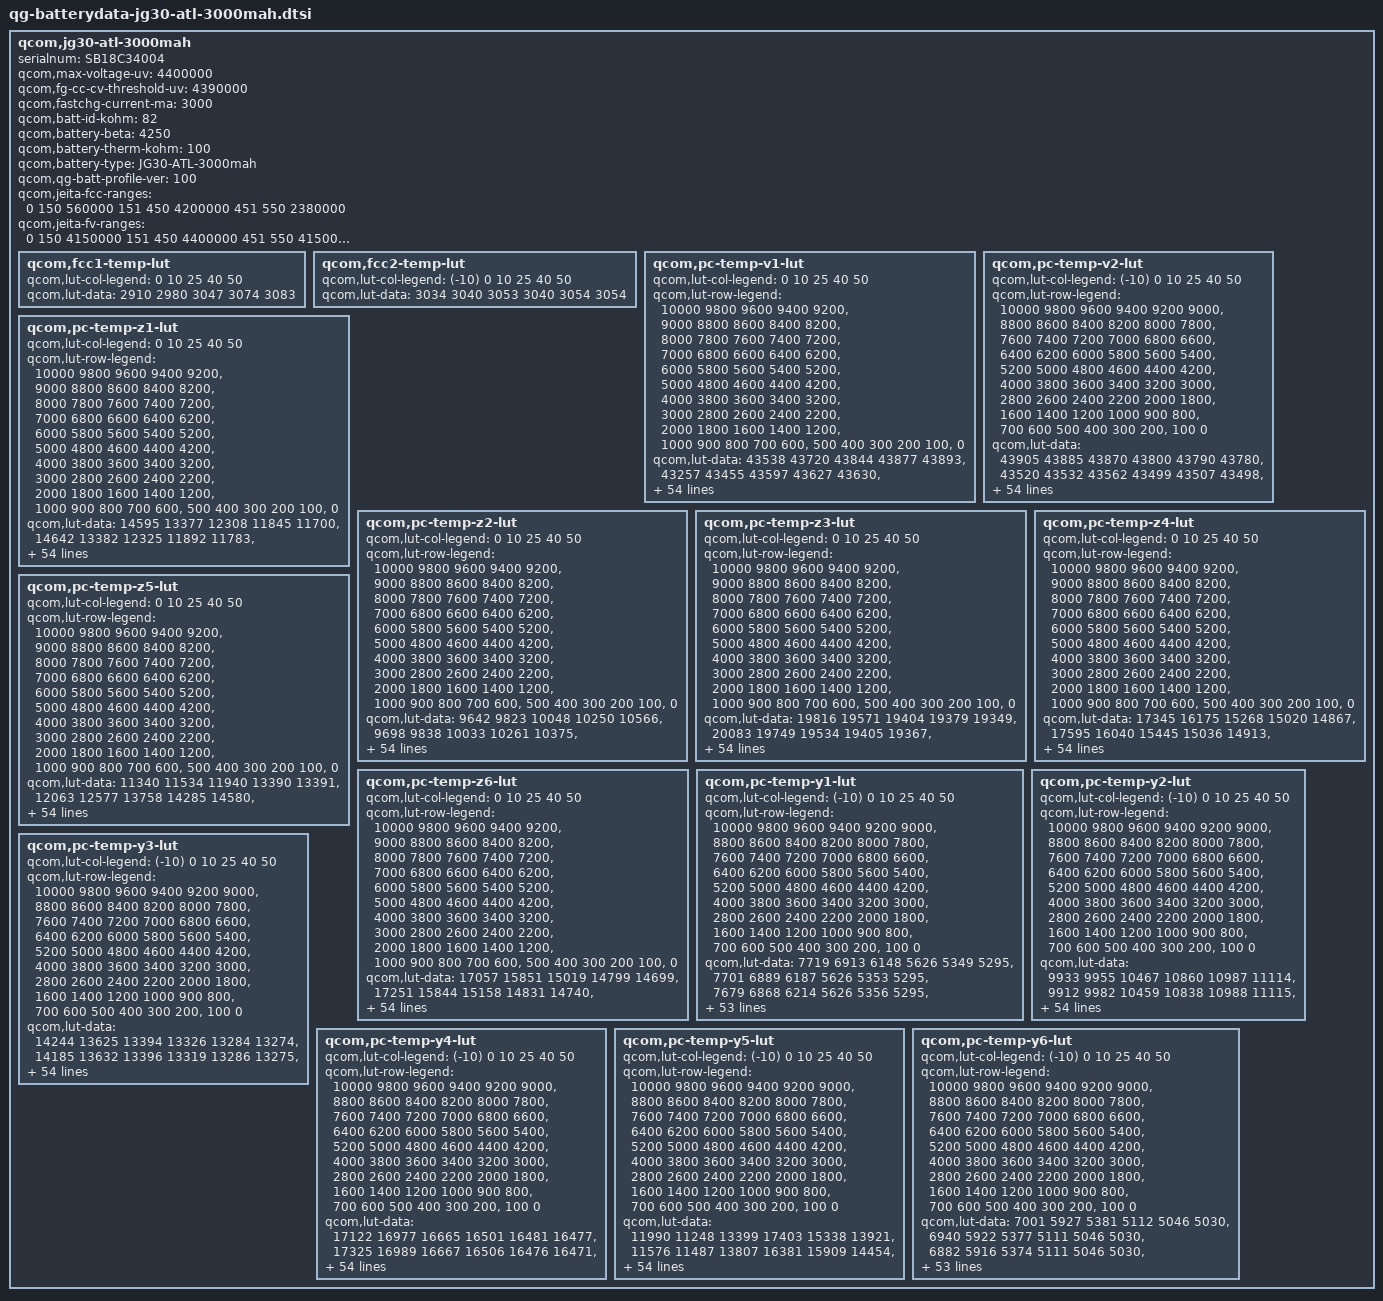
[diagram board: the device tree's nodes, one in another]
/* Copyright (c) 2018, The Linux Foundation. All rights reserved.
 *
 * This program is free software; you can redistribute it and/or modify
 * it under the terms of the GNU General Public License version 2 and
 * only version 2 as published by the Free Software Foundation.
 *
 * This program is distributed in the hope that it will be useful,
 * but WITHOUT ANY WARRANTY; without even the implied warranty of
 * MERCHANTABILITY or FITNESS FOR A PARTICULAR PURPOSE.  See the
 * GNU General Public License for more details.
 */

qcom,jg30-atl-3000mah {
	serialnum = "SB18C34004";
	qcom,max-voltage-uv = <4400000>;
	qcom,fg-cc-cv-threshold-uv = <4390000>;
	qcom,fastchg-current-ma = <3000>;
	qcom,batt-id-kohm = <82>;
	qcom,battery-beta = <4250>;
	qcom,battery-therm-kohm = <100>;
	qcom,battery-type = "JG30-ATL-3000mah";
	qcom,qg-batt-profile-ver = <100>;

	qcom,jeita-fcc-ranges = <0   150   560000
				 151 450  4200000
				 451 550  2380000>;
	qcom,jeita-fv-ranges =  <0   150  4150000
				 151 450  4400000
				 451 550  4150000>;

	qcom,fcc1-temp-lut {
		qcom,lut-col-legend = <0 10 25 40 50>;
		qcom,lut-data = <2910 2980 3047 3074 3083>;
	};

	qcom,fcc2-temp-lut {
		qcom,lut-col-legend = <(-10) 0 10 25 40 50>;
		qcom,lut-data = <3034 3040 3053 3040 3054 3054>;
	};

	qcom,pc-temp-v1-lut {
		qcom,lut-col-legend = <0 10 25 40 50>;
		qcom,lut-row-legend = <10000 9800 9600 9400 9200>,
			<9000 8800 8600 8400 8200>,
			<8000 7800 7600 7400 7200>,
			<7000 6800 6600 6400 6200>,
			<6000 5800 5600 5400 5200>,
			<5000 4800 4600 4400 4200>,
			<4000 3800 3600 3400 3200>,
			<3000 2800 2600 2400 2200>,
			<2000 1800 1600 1400 1200>,
			<1000 900 800 700 600>,
			<500 400 300 200 100>,
			<0>;
		qcom,lut-data = <43538 43720 43844 43877 43893>,
			<43257 43455 43597 43627 43630>,
			<43002 43198 43351 43385 43391>,
			<42762 42951 43108 43148 43155>,
			<42526 42711 42866 42911 42921>,
			<42294 42475 42624 42672 42685>,
			<42067 42244 42386 42436 42451>,
			<41845 42018 42150 42200 42219>,
			<41629 41795 41919 41968 41988>,
			<41423 41576 41692 41738 41759>,
			<41235 41366 41469 41511 41530>,
			<41048 41170 41256 41291 41307>,
			<40836 40974 41056 41077 41090>,
			<40602 40760 40857 40871 40880>,
			<40378 40534 40645 40664 40674>,
			<40167 40323 40430 40458 40473>,
			<39973 40130 40233 40264 40280>,
			<39813 39953 40051 40087 40100>,
			<39680 39802 39882 39918 39928>,
			<39556 39670 39736 39758 39763>,
			<39430 39534 39595 39605 39607>,
			<39306 39393 39409 39423 39430>,
			<39184 39243 39158 39165 39196>,
			<39063 39059 38938 38928 38968>,
			<38946 38843 38781 38787 38815>,
			<38832 38675 38653 38681 38695>,
			<38722 38561 38554 38580 38583>,
			<38620 38471 38478 38483 38477>,
			<38526 38402 38406 38393 38380>,
			<38440 38347 38337 38309 38292>,
			<38369 38298 38273 38232 38213>,
			<38308 38253 38212 38164 38142>,
			<38257 38212 38157 38104 38079>,
			<38218 38175 38108 38049 38020>,
			<38184 38141 38068 38002 37967>,
			<38150 38106 38030 37957 37915>,
			<38117 38074 37991 37908 37854>,
			<38079 38038 37952 37858 37787>,
			<38027 37983 37898 37795 37713>,
			<37960 37897 37809 37711 37633>,
			<37876 37798 37703 37611 37543>,
			<37759 37687 37592 37500 37436>,
			<37624 37559 37467 37374 37308>,
			<37470 37403 37314 37221 37155>,
			<37342 37260 37170 37079 37014>,
			<37242 37161 37074 36988 36928>,
			<37206 37131 37047 36965 36904>,
			<37181 37117 37031 36949 36888>,
			<37154 37091 37012 36929 36869>,
			<37099 37042 36959 36865 36791>,
			<36873 36804 36703 36587 36499>,
			<36429 36374 36269 36148 36060>,
			<35857 35803 35698 35575 35485>,
			<35079 35024 34917 34790 34700>,
			<33852 33805 33700 33566 33474>,
			<30000 30000 30000 30000 30000>;
	};

	qcom,pc-temp-v2-lut {
		qcom,lut-col-legend = <(-10) 0 10 25 40 50>;
		qcom,lut-row-legend = <10000 9800 9600 9400 9200 9000>,
			<8800 8600 8400 8200 8000 7800>,
			<7600 7400 7200 7000 6800 6600>,
			<6400 6200 6000 5800 5600 5400>,
			<5200 5000 4800 4600 4400 4200>,
			<4000 3800 3600 3400 3200 3000>,
			<2800 2600 2400 2200 2000 1800>,
			<1600 1400 1200 1000 900 800>,
			<700 600 500 400 300 200>,
			<100 0>;
		qcom,lut-data = <43905 43885 43870 43800 43790 43780>,
			<43520 43532 43562 43499 43507 43498>,
			<43172 43212 43274 43216 43239 43231>,
			<42866 42927 43008 42955 42985 42979>,
			<42594 42675 42764 42714 42746 42742>,
			<42345 42432 42524 42478 42511 42508>,
			<42122 42189 42286 42243 42275 42274>,
			<41909 41953 42051 42012 42042 42041>,
			<41669 41728 41822 41783 41812 41813>,
			<41406 41512 41597 41557 41586 41588>,
			<41178 41301 41378 41335 41363 41366>,
			<41017 41098 41168 41118 41142 41147>,
			<40859 40897 40961 40906 40927 40932>,
			<40618 40693 40760 40701 40723 40725>,
			<40287 40484 40562 40501 40526 40524>,
			<39980 40246 40348 40304 40332 40330>,
			<39711 39924 40107 40104 40133 40143>,
			<39475 39618 39866 39912 39943 39962>,
			<39298 39428 39646 39744 39777 39793>,
			<39154 39287 39439 39590 39623 39629>,
			<39009 39139 39249 39410 39441 39443>,
			<38855 38973 39073 39176 39211 39217>,
			<38707 38816 38911 38949 38992 39003>,
			<38566 38683 38763 38780 38817 38828>,
			<38431 38564 38626 38638 38664 38674>,
			<38321 38437 38504 38514 38536 38544>,
			<38233 38289 38392 38407 38428 38434>,
			<38156 38162 38290 38309 38330 38335>,
			<38084 38081 38198 38218 38239 38242>,
			<38017 38018 38111 38134 38155 38156>,
			<37956 37963 38027 38059 38080 38080>,
			<37898 37914 37944 37991 38012 38009>,
			<37843 37868 37876 37928 37946 37943>,
			<37785 37822 37827 37868 37885 37885>,
			<37728 37777 37784 37812 37823 37826>,
			<37669 37731 37742 37753 37745 37737>,
			<37609 37686 37701 37692 37651 37613>,
			<37548 37635 37656 37628 37559 37502>,
			<37484 37574 37604 37558 37475 37412>,
			<37420 37504 37543 37481 37392 37328>,
			<37355 37424 37467 37400 37312 37248>,
			<37290 37330 37371 37309 37230 37167>,
			<37222 37226 37254 37203 37126 37063>,
			<37148 37112 37118 37076 36995 36930>,
			<37064 37005 36984 36929 36857 36799>,
			<36958 36904 36903 36882 36824 36767>,
			<36900 36860 36880 36867 36811 36755>,
			<36832 36814 36853 36847 36792 36736>,
			<36733 36753 36810 36815 36756 36700>,
			<36563 36651 36724 36722 36645 36570>,
			<36270 36427 36459 36432 36320 36225>,
			<35826 35992 35959 35954 35825 35727>,
			<35194 35365 35320 35333 35181 35075>,
			<34288 34476 34430 34484 34284 34175>,
			<32894 33067 33017 33162 32942 32812>,
			<29087 28386 28468 27721 27827 28047>;
	};

	qcom,pc-temp-z1-lut {
		qcom,lut-col-legend = <0 10 25 40 50>;
		qcom,lut-row-legend = <10000 9800 9600 9400 9200>,
			<9000 8800 8600 8400 8200>,
			<8000 7800 7600 7400 7200>,
			<7000 6800 6600 6400 6200>,
			<6000 5800 5600 5400 5200>,
			<5000 4800 4600 4400 4200>,
			<4000 3800 3600 3400 3200>,
			<3000 2800 2600 2400 2200>,
			<2000 1800 1600 1400 1200>,
			<1000 900 800 700 600>,
			<500 400 300 200 100>,
			<0>;
		qcom,lut-data = <14595 13377 12308 11845 11700>,
			<14642 13382 12325 11892 11783>,
			<14662 13381 12320 11887 11783>,
			<14673 13373 12310 11888 11785>,
			<14669 13362 12303 11887 11787>,
			<14638 13351 12297 11883 11788>,
			<14613 13337 12290 11880 11789>,
			<14604 13323 12280 11880 11789>,
			<14580 13313 12273 11881 11787>,
			<14567 13305 12273 11880 11787>,
			<14564 13300 12275 11878 11788>,
			<14562 13295 12276 11876 11789>,
			<14554 13288 12275 11878 11790>,
			<14517 13270 12273 11880 11791>,
			<14485 13240 12272 11880 11791>,
			<14432 13228 12270 11879 11791>,
			<14370 13231 12270 11879 11791>,
			<14357 13239 12274 11882 11792>,
			<14373 13249 12278 11887 11795>,
			<14390 13265 12283 11889 11797>,
			<14403 13275 12289 11891 11799>,
			<14422 13279 12295 11893 11801>,
			<14438 13283 12301 11895 11802>,
			<14463 13291 12307 11896 11804>,
			<14482 13305 12313 11900 11806>,
			<14487 13311 12319 11905 11810>,
			<14493 13307 12328 11910 11814>,
			<14492 13304 12342 11915 11819>,
			<14484 13304 12352 11920 11823>,
			<14472 13308 12357 11926 11826>,
			<14459 13315 12362 11932 11829>,
			<14444 13325 12368 11937 11833>,
			<14436 13340 12379 11941 11838>,
			<14461 13354 12389 11945 11842>,
			<14507 13370 12396 11951 11845>,
			<14537 13380 12404 11957 11848>,
			<14580 13389 12414 11962 11851>,
			<14609 13399 12426 11967 11854>,
			<14593 13416 12435 11971 11856>,
			<14558 13448 12440 11974 11858>,
			<14541 13467 12446 11978 11860>,
			<14559 13465 12456 11983 11862>,
			<14568 13462 12466 11987 11866>,
			<14559 13457 12469 11991 11870>,
			<14557 13472 12479 11997 11873>,
			<14539 13460 12488 12002 11875>,
			<14539 13434 12490 12002 11876>,
			<14577 13435 12483 12004 11877>,
			<14567 13446 12480 12004 11880>,
			<14538 13462 12491 12008 11882>,
			<14587 13474 12508 12017 11886>,
			<14663 13499 12521 12024 11895>,
			<14618 13540 12539 12036 11905>,
			<14678 13567 12570 12055 11919>,
			<14678 13567 12570 12055 11919>,
			<14678 13567 12570 12055 11919>;
	};

	qcom,pc-temp-z2-lut {
		qcom,lut-col-legend = <0 10 25 40 50>;
		qcom,lut-row-legend = <10000 9800 9600 9400 9200>,
			<9000 8800 8600 8400 8200>,
			<8000 7800 7600 7400 7200>,
			<7000 6800 6600 6400 6200>,
			<6000 5800 5600 5400 5200>,
			<5000 4800 4600 4400 4200>,
			<4000 3800 3600 3400 3200>,
			<3000 2800 2600 2400 2200>,
			<2000 1800 1600 1400 1200>,
			<1000 900 800 700 600>,
			<500 400 300 200 100>,
			<0>;
		qcom,lut-data = <9642 9823 10048 10250 10566>,
			<9698 9838 10033 10261 10375>,
			<9747 9842 10039 10306 10461>,
			<9792 9830 10045 10320 10473>,
			<9803 9812 10039 10320 10474>,
			<9800 9805 10016 10289 10433>,
			<9797 9804 10001 10261 10385>,
			<9794 9804 9993 10265 10392>,
			<9790 9801 9988 10278 10422>,
			<9786 9795 9997 10293 10438>,
			<9782 9792 10022 10312 10428>,
			<9776 9790 10039 10322 10411>,
			<9763 9789 10049 10319 10384>,
			<9737 9790 10057 10312 10345>,
			<9723 9791 10063 10297 10340>,
			<9725 9795 10070 10256 10349>,
			<9731 9807 10077 10240 10361>,
			<9738 9826 10089 10252 10375>,
			<9751 9850 10099 10265 10392>,
			<9762 9883 10105 10270 10401>,
			<9767 9897 10110 10281 10408>,
			<9771 9898 10117 10299 10409>,
			<9770 9899 10129 10356 10392>,
			<9753 9902 10135 10402 10375>,
			<9738 9910 10124 10363 10389>,
			<9737 9916 10108 10273 10435>,
			<9737 9920 10106 10258 10479>,
			<9738 9923 10110 10354 10529>,
			<9743 9922 10115 10427 10560>,
			<9750 9919 10123 10399 10498>,
			<9757 9917 10132 10345 10373>,
			<9764 9919 10133 10321 10321>,
			<9771 9921 10130 10309 10295>,
			<9778 9925 10127 10304 10283>,
			<9786 9931 10123 10324 10331>,
			<9795 9939 10120 10356 10422>,
			<9808 9947 10122 10376 10499>,
			<9822 9955 10130 10404 10597>,
			<9836 9963 10140 10425 10636>,
			<9851 9973 10165 10462 10617>,
			<9866 9979 10185 10496 10587>,
			<9880 9982 10182 10484 10557>,
			<9902 9985 10175 10453 10527>,
			<9950 10001 10186 10469 10515>,
			<9986 10127 10239 10474 10522>,
			<9962 10203 10280 10451 10511>,
			<9919 10213 10285 10438 10481>,
			<9866 10400 10322 10423 10490>,
			<9885 10397 10321 10419 10515>,
			<9875 10432 10354 10535 10671>,
			<9838 10354 10440 10527 10429>,
			<9807 10394 10432 10461 10429>,
			<9671 10285 10389 10390 10327>,
			<9580 10173 10377 10298 10263>,
			<9580 10173 10377 10298 10263>,
			<9580 10173 10377 10298 10263>;
	};

	qcom,pc-temp-z3-lut {
		qcom,lut-col-legend = <0 10 25 40 50>;
		qcom,lut-row-legend = <10000 9800 9600 9400 9200>,
			<9000 8800 8600 8400 8200>,
			<8000 7800 7600 7400 7200>,
			<7000 6800 6600 6400 6200>,
			<6000 5800 5600 5400 5200>,
			<5000 4800 4600 4400 4200>,
			<4000 3800 3600 3400 3200>,
			<3000 2800 2600 2400 2200>,
			<2000 1800 1600 1400 1200>,
			<1000 900 800 700 600>,
			<500 400 300 200 100>,
			<0>;
		qcom,lut-data = <19816 19571 19404 19379 19349>,
			<20083 19749 19534 19405 19367>,
			<20077 19862 19572 19445 19408>,
			<20054 19893 19591 19461 19428>,
			<20028 19910 19598 19467 19436>,
			<19991 19913 19602 19469 19437>,
			<19966 19901 19603 19470 19436>,
			<19965 19883 19598 19464 19428>,
			<19968 19868 19589 19451 19412>,
			<19971 19851 19575 19442 19403>,
			<19974 19839 19555 19435 19399>,
			<19978 19831 19537 19427 19394>,
			<19986 19823 19519 19418 19382>,
			<20003 19813 19508 19409 19366>,
			<20011 19799 19506 19402 19361>,
			<19999 19781 19506 19395 19359>,
			<19976 19757 19505 19391 19357>,
			<19951 19730 19503 19389 19352>,
			<19916 19704 19501 19387 19345>,
			<19891 19679 19496 19385 19343>,
			<19884 19670 19491 19382 19342>,
			<19881 19684 19496 19382 19342>,
			<19888 19708 19527 19399 19348>,
			<19938 19734 19546 19416 19355>,
			<19993 19765 19540 19404 19350>,
			<20020 19777 19530 19378 19334>,
			<20043 19776 19520 19371 19331>,
			<20051 19772 19509 19380 19365>,
			<20050 19766 19504 19393 19395>,
			<20048 19756 19507 19410 19396>,
			<20043 19746 19512 19427 19392>,
			<20030 19737 19519 19429 19388>,
			<20014 19727 19529 19423 19377>,
			<19992 19720 19533 19417 19369>,
			<19966 19713 19529 19413 19366>,
			<19943 19707 19522 19409 19365>,
			<19922 19699 19516 19406 19365>,
			<19902 19691 19509 19403 19367>,
			<19884 19687 19505 19401 19368>,
			<19867 19684 19503 19399 19365>,
			<19851 19682 19501 19397 19361>,
			<19839 19670 19497 19395 19357>,
			<19823 19656 19490 19392 19353>,
			<19789 19642 19484 19388 19353>,
			<19476 19581 19465 19379 19349>,
			<19376 19531 19447 19372 19339>,
			<19368 19528 19442 19364 19338>,
			<19349 19369 19422 19359 19336>,
			<19342 19411 19425 19358 19329>,
			<19337 19446 19414 19347 19326>,
			<19347 19480 19396 19351 19355>,
			<19363 19371 19388 19361 19339>,
			<19376 19359 19387 19360 19350>,
			<19383 19353 19375 19371 19356>,
			<19383 19353 19375 19371 19356>,
			<19383 19353 19375 19371 19356>;
	};

	qcom,pc-temp-z4-lut {
		qcom,lut-col-legend = <0 10 25 40 50>;
		qcom,lut-row-legend = <10000 9800 9600 9400 9200>,
			<9000 8800 8600 8400 8200>,
			<8000 7800 7600 7400 7200>,
			<7000 6800 6600 6400 6200>,
			<6000 5800 5600 5400 5200>,
			<5000 4800 4600 4400 4200>,
			<4000 3800 3600 3400 3200>,
			<3000 2800 2600 2400 2200>,
			<2000 1800 1600 1400 1200>,
			<1000 900 800 700 600>,
			<500 400 300 200 100>,
			<0>;
		qcom,lut-data = <17345 16175 15268 15020 14867>,
			<17595 16040 15445 15036 14913>,
			<17416 15886 15332 15062 14954>,
			<17023 15698 15173 14987 14905>,
			<16712 15485 15079 14929 14860>,
			<16466 15330 15007 14888 14827>,
			<16253 15225 14950 14856 14803>,
			<16077 15144 14900 14831 14790>,
			<15926 15082 14863 14810 14781>,
			<15800 15034 14844 14796 14772>,
			<15694 14988 14831 14787 14761>,
			<15604 14938 14822 14779 14754>,
			<15530 14901 14815 14771 14753>,
			<15466 14889 14809 14764 14752>,
			<15413 14883 14805 14758 14748>,
			<15369 14878 14799 14753 14736>,
			<15330 14874 14788 14746 14724>,
			<15291 14870 14764 14729 14714>,
			<15254 14864 14744 14712 14706>,
			<15221 14855 14734 14709 14702>,
			<15191 14843 14727 14708 14699>,
			<15160 14815 14737 14712 14701>,
			<15120 14791 14798 14786 14766>,
			<15048 14806 14852 14863 14843>,
			<14982 14864 14880 14881 14863>,
			<14946 14896 14897 14891 14873>,
			<14919 14901 14896 14890 14870>,
			<14908 14903 14880 14862 14819>,
			<14906 14899 14861 14826 14764>,
			<14904 14880 14838 14788 14743>,
			<14903 14861 14813 14751 14728>,
			<14900 14848 14790 14733 14717>,
			<14899 14835 14768 14723 14709>,
			<14898 14822 14753 14717 14704>,
			<14898 14809 14745 14714 14703>,
			<14896 14798 14740 14713 14702>,
			<14892 14788 14739 14715 14707>,
			<14888 14780 14738 14725 14727>,
			<14883 14779 14739 14733 14737>,
			<14876 14779 14747 14740 14736>,
			<14868 14779 14755 14744 14735>,
			<14859 14779 14750 14739 14730>,
			<14851 14779 14741 14727 14722>,
			<14843 14773 14740 14729 14723>,
			<15025 14762 14730 14725 14721>,
			<15090 14761 14705 14699 14699>,
			<15096 14755 14698 14692 14685>,
			<15110 14924 14706 14677 14665>,
			<15106 14867 14691 14660 14653>,
			<15094 14815 14699 14679 14667>,
			<15084 14792 14744 14704 14660>,
			<15101 14929 14761 14697 14681>,
			<15110 14955 14768 14701 14670>,
			<15130 14976 14786 14692 14665>,
			<15130 14976 14786 14692 14665>,
			<15130 14976 14786 14692 14665>;
	};

	qcom,pc-temp-z5-lut {
		qcom,lut-col-legend = <0 10 25 40 50>;
		qcom,lut-row-legend = <10000 9800 9600 9400 9200>,
			<9000 8800 8600 8400 8200>,
			<8000 7800 7600 7400 7200>,
			<7000 6800 6600 6400 6200>,
			<6000 5800 5600 5400 5200>,
			<5000 4800 4600 4400 4200>,
			<4000 3800 3600 3400 3200>,
			<3000 2800 2600 2400 2200>,
			<2000 1800 1600 1400 1200>,
			<1000 900 800 700 600>,
			<500 400 300 200 100>,
			<0>;
		qcom,lut-data = <11340 11534 11940 13390 13391>,
			<12063 12577 13758 14285 14580>,
			<12280 13383 14414 15148 15772>,
			<12405 13921 14862 15642 16791>,
			<12539 14333 15282 15986 17388>,
			<12680 14627 15643 16254 17723>,
			<12820 14838 16041 16419 17888>,
			<12965 15012 16600 16556 17648>,
			<13110 15157 16986 16742 17181>,
			<13249 15281 16962 16816 17049>,
			<13384 15504 16840 16821 17303>,
			<13509 16159 16689 16782 17424>,
			<13615 16894 16303 16685 16804>,
			<13716 17329 15985 16536 15906>,
			<13759 17679 15994 16345 15788>,
			<13709 17764 16092 16083 16153>,
			<13613 17069 16397 16001 16485>,
			<13509 16239 17658 16865 16624>,
			<13354 16020 18980 18091 16753>,
			<13240 15903 19707 18670 17063>,
			<13267 15923 20461 19029 17760>,
			<13426 17747 23797 19923 18517>,
			<13751 21205 35472 24300 19498>,
			<15008 26808 42453 28125 20228>,
			<16744 35814 37517 25192 18915>,
			<18647 39674 29242 18287 15331>,
			<21038 37407 24637 16124 14224>,
			<23014 33812 21327 15956 15792>,
			<24730 31099 20049 15889 17564>,
			<25921 28641 20074 17169 18713>,
			<25986 26826 20244 19855 19874>,
			<25613 25444 21412 21900 20505>,
			<25077 24464 24722 23570 21079>,
			<23717 24160 26817 25101 21809>,
			<21810 24011 27941 26993 23793>,
			<20585 23939 28689 28550 26109>,
			<19700 23765 28362 28491 26332>,
			<19087 23562 27191 27369 25690>,
			<18709 23802 26519 26059 24731>,
			<18423 24832 25797 23877 22632>,
			<18406 25402 24955 21890 20361>,
			<19021 23614 24116 21326 19365>,
			<19309 22090 23102 20990 18727>,
			<18827 21645 21817 19684 17970>,
			<13414 20098 21326 18600 17212>,
			<11611 17964 21464 19581 17169>,
			<11525 17959 20665 18468 17708>,
			<11339 11960 18333 18748 19076>,
			<11294 12748 18252 20112 20003>,
			<11301 13715 17268 17093 17164>,
			<11439 15300 14868 15070 18944>,
			<11455 11977 14044 15442 15654>,
			<11416 11680 13775 15014 16714>,
			<11332 11490 12967 15827 17484>,
			<11332 11490 12967 15827 17484>,
			<11332 11490 12967 15827 17484>;
	};

	qcom,pc-temp-z6-lut {
		qcom,lut-col-legend = <0 10 25 40 50>;
		qcom,lut-row-legend = <10000 9800 9600 9400 9200>,
			<9000 8800 8600 8400 8200>,
			<8000 7800 7600 7400 7200>,
			<7000 6800 6600 6400 6200>,
			<6000 5800 5600 5400 5200>,
			<5000 4800 4600 4400 4200>,
			<4000 3800 3600 3400 3200>,
			<3000 2800 2600 2400 2200>,
			<2000 1800 1600 1400 1200>,
			<1000 900 800 700 600>,
			<500 400 300 200 100>,
			<0>;
		qcom,lut-data = <17057 15851 15019 14799 14699>,
			<17251 15844 15158 14831 14740>,
			<17152 15826 15122 14857 14773>,
			<16930 15773 15069 14837 14765>,
			<16751 15664 15032 14819 14755>,
			<16602 15576 15000 14803 14744>,
			<16477 15514 14972 14788 14732>,
			<16386 15462 14948 14773 14721>,
			<16313 15419 14926 14758 14709>,
			<16253 15384 14908 14746 14700>,
			<16203 15354 14893 14738 14693>,
			<16159 15328 14879 14730 14687>,
			<16116 15305 14867 14722 14680>,
			<16076 15285 14858 14715 14672>,
			<16038 15267 14854 14708 14666>,
			<16002 15251 14851 14702 14660>,
			<15968 15237 14846 14696 14654>,
			<15933 15224 14834 14687 14646>,
			<15897 15210 14825 14680 14640>,
			<15870 15194 14819 14677 14637>,
			<15854 15188 14815 14675 14635>,
			<15843 15189 14822 14677 14635>,
			<15840 15190 14867 14721 14669>,
			<15842 15205 14900 14762 14706>,
			<15844 15251 14909 14762 14708>,
			<15846 15276 14913 14756 14707>,
			<15849 15280 14912 14750 14706>,
			<15852 15282 14901 14744 14702>,
			<15853 15279 14891 14738 14696>,
			<15854 15268 14884 14732 14689>,
			<15853 15257 14878 14726 14681>,
			<15849 15249 14874 14719 14673>,
			<15844 15241 14871 14712 14664>,
			<15837 15235 14868 14707 14659>,
			<15828 15229 14864 14704 14656>,
			<15820 15225 14861 14702 14655>,
			<15812 15222 14859 14702 14657>,
			<15806 15220 14857 14705 14667>,
			<15802 15220 14856 14708 14672>,
			<15800 15224 14861 14710 14671>,
			<15796 15227 14865 14712 14669>,
			<15786 15226 14863 14709 14664>,
			<15775 15224 14857 14703 14659>,
			<15762 15220 14856 14702 14660>,
			<15693 15194 14846 14697 14658>,
			<15669 15174 14828 14683 14643>,
			<15667 15169 14823 14676 14637>,
			<15661 15162 14817 14666 14627>,
			<15660 15160 14811 14659 14618>,
			<15658 15161 14812 14662 14622>,
			<15673 15174 14825 14676 14637>,
			<15702 15187 14831 14680 14640>,
			<15732 15207 14840 14684 14643>,
			<15778 15236 14850 14690 14647>,
			<15778 15236 14850 14690 14647>,
			<15778 15236 14850 14690 14647>;
	};

	qcom,pc-temp-y1-lut {
		qcom,lut-col-legend = <(-10) 0 10 25 40 50>;
		qcom,lut-row-legend = <10000 9800 9600 9400 9200 9000>,
			<8800 8600 8400 8200 8000 7800>,
			<7600 7400 7200 7000 6800 6600>,
			<6400 6200 6000 5800 5600 5400>,
			<5200 5000 4800 4600 4400 4200>,
			<4000 3800 3600 3400 3200 3000>,
			<2800 2600 2400 2200 2000 1800>,
			<1600 1400 1200 1000 900 800>,
			<700 600 500 400 300 200>,
			<100 0>;
		qcom,lut-data = <7719 6913 6148 5626 5349 5295>,
			<7701 6889 6187 5626 5353 5295>,
			<7679 6868 6214 5626 5356 5295>,
			<7658 6850 6230 5624 5357 5295>,
			<7642 6837 6238 5622 5358 5294>,
			<7634 6832 6240 5620 5358 5294>,
			<7633 6836 6228 5614 5357 5294>,
			<7633 6841 6212 5607 5355 5293>,
			<7631 6840 6209 5604 5354 5293>,
			<7618 6835 6209 5602 5353 5291>,
			<7611 6830 6207 5601 5352 5290>,
			<7613 6821 6193 5599 5351 5290>,
			<7619 6813 6178 5597 5350 5290>,
			<7626 6816 6177 5596 5349 5290>,
			<7633 6827 6178 5595 5349 5289>,
			<7636 6833 6179 5595 5349 5289>,
			<7618 6830 6184 5598 5351 5291>,
			<7596 6826 6188 5602 5353 5292>,
			<7595 6829 6193 5604 5353 5293>,
			<7602 6837 6202 5606 5352 5293>,
			<7605 6842 6204 5608 5352 5293>,
			<7615 6842 6193 5610 5353 5294>,
			<7624 6841 6184 5612 5354 5295>,
			<7608 6846 6197 5617 5356 5295>,
			<7569 6856 6222 5625 5360 5296>,
			<7553 6855 6226 5630 5362 5297>,
			<7551 6832 6218 5634 5363 5299>,
			<7549 6813 6211 5638 5365 5301>,
			<7551 6811 6216 5647 5368 5303>,
			<7557 6811 6225 5659 5373 5305>,
			<7557 6807 6229 5666 5377 5308>,
			<7545 6797 6233 5671 5379 5311>,
			<7533 6790 6234 5675 5382 5313>,
			<7539 6800 6230 5679 5387 5315>,
			<7557 6817 6226 5686 5392 5318>,
			<7568 6818 6227 5699 5396 5320>,
			<7599 6802 6230 5729 5399 5322>,
			<7623 6789 6232 5746 5402 5324>,
			<7596 6793 6234 5730 5404 5325>,
			<7549 6799 6236 5708 5405 5327>,
			<7527 6792 6239 5707 5407 5328>,
			<7507 6769 6242 5711 5408 5331>,
			<7507 6772 6262 5717 5411 5332>,
			<7526 6798 6283 5726 5414 5333>,
			<7565 6836 6274 5734 5417 5335>,
			<7658 6861 6293 5740 5419 5338>,
			<7630 6796 6288 5747 5422 5339>,
			<7641 6834 6286 5746 5423 5340>,
			<7689 6836 6284 5756 5423 5340>,
			<7659 6839 6291 5761 5425 5341>,
			<7639 6824 6265 5760 5428 5343>,
			<7599 6837 6292 5777 5434 5349>,
			<7665 6831 6304 5797 5445 5355>,
			<7824 6912 6319 5817 5458 5365>,
			<7824 6912 6319 5817 5458 5365>,
			<7824 6912 6319 5817 5458 5365>;
	};

	qcom,pc-temp-y2-lut {
		qcom,lut-col-legend = <(-10) 0 10 25 40 50>;
		qcom,lut-row-legend = <10000 9800 9600 9400 9200 9000>,
			<8800 8600 8400 8200 8000 7800>,
			<7600 7400 7200 7000 6800 6600>,
			<6400 6200 6000 5800 5600 5400>,
			<5200 5000 4800 4600 4400 4200>,
			<4000 3800 3600 3400 3200 3000>,
			<2800 2600 2400 2200 2000 1800>,
			<1600 1400 1200 1000 900 800>,
			<700 600 500 400 300 200>,
			<100 0>;
		qcom,lut-data = <9933 9955 10467 10860 10987 11114>,
			<9912 9982 10459 10838 10988 11115>,
			<9907 10014 10448 10817 10992 11112>,
			<9915 10045 10436 10798 10997 11105>,
			<9933 10071 10425 10780 11001 11095>,
			<9956 10086 10418 10764 11002 11082>,
			<9987 10093 10413 10749 11002 11038>,
			<10030 10098 10410 10736 11000 10991>,
			<10095 10108 10411 10733 10991 11001>,
			<10197 10124 10417 10732 10961 11055>,
			<10245 10152 10421 10730 10948 11081>,
			<10243 10266 10421 10719 10950 11076>,
			<10241 10386 10422 10708 10952 11064>,
			<10264 10394 10446 10708 10948 11042>,
			<10340 10384 10512 10715 10936 11004>,
			<10376 10380 10550 10725 10938 10995>,
			<10244 10393 10564 10747 10987 11065>,
			<10079 10416 10574 10774 11049 11157>,
			<9977 10449 10584 10800 11098 11228>,
			<9771 10498 10593 10826 11150 11291>,
			<9690 10535 10605 10834 11160 11306>,
			<9683 10566 10624 10832 11116 11257>,
			<9679 10584 10645 10831 11078 11218>,
			<9674 10572 10664 10840 11068 11204>,
			<9671 10544 10681 10865 11053 11180>,
			<9668 10536 10696 10882 11058 11191>,
			<9666 10541 10710 10895 11087 11254>,
			<9665 10546 10718 10906 11118 11299>,
			<9664 10542 10717 10915 11141 11290>,
			<9663 10528 10714 10924 11162 11269>,
			<9662 10454 10715 10932 11186 11281>,
			<9661 10049 10723 10941 11218 11332>,
			<9661 9737 10727 10946 11236 11384>,
			<9660 9708 10718 10937 11233 11432>,
			<9660 9693 10702 10918 11223 11470>,
			<9659 9683 10688 10908 11203 11434>,
			<9659 9676 10672 10897 11154 11286>,
			<9658 9670 10658 10892 11117 11195>,
			<9658 9667 10648 10886 11099 11180>,
			<9657 9665 10637 10875 11088 11181>,
			<9657 9662 10619 10873 11082 11195>,
			<9657 9660 10593 10873 11079 11214>,
			<9656 9658 10562 10859 11109 11174>,
			<9656 9657 10514 10827 11125 11171>,
			<9656 9656 10479 10829 11092 11171>,
			<9656 9656 10438 10806 11024 11066>,
			<9655 9655 10406 10782 11022 11042>,
			<9655 9655 10377 10778 10994 11024>,
			<9654 9654 10356 10780 10986 11016>,
			<9654 9653 10337 10755 10964 10973>,
			<9654 9653 10194 10735 10936 10953>,
			<9653 9652 9828 10688 10900 10885>,
			<9652 9652 9699 10661 10874 10859>,
			<9649 9651 9667 10615 10799 10775>,
			<9649 9651 9667 10615 10799 10775>,
			<9649 9651 9667 10615 10799 10775>;
	};

	qcom,pc-temp-y3-lut {
		qcom,lut-col-legend = <(-10) 0 10 25 40 50>;
		qcom,lut-row-legend = <10000 9800 9600 9400 9200 9000>,
			<8800 8600 8400 8200 8000 7800>,
			<7600 7400 7200 7000 6800 6600>,
			<6400 6200 6000 5800 5600 5400>,
			<5200 5000 4800 4600 4400 4200>,
			<4000 3800 3600 3400 3200 3000>,
			<2800 2600 2400 2200 2000 1800>,
			<1600 1400 1200 1000 900 800>,
			<700 600 500 400 300 200>,
			<100 0>;
		qcom,lut-data = <14244 13625 13394 13326 13284 13274>,
			<14185 13632 13396 13319 13286 13275>,
			<14113 13634 13399 13314 13288 13277>,
			<14042 13634 13401 13312 13289 13278>,
			<13983 13632 13404 13311 13290 13279>,
			<13949 13629 13404 13312 13292 13280>,
			<13937 13620 13404 13315 13294 13281>,
			<13928 13609 13404 13319 13295 13282>,
			<13903 13614 13404 13320 13295 13284>,
			<13847 13638 13406 13320 13296 13289>,
			<13781 13649 13407 13320 13296 13291>,
			<13690 13605 13411 13322 13296 13292>,
			<13613 13551 13414 13323 13297 13293>,
			<13610 13542 13414 13324 13299 13292>,
			<13626 13541 13413 13326 13304 13292>,
			<13632 13537 13412 13328 13306 13292>,
			<13579 13513 13409 13328 13303 13295>,
			<13520 13483 13406 13329 13301 13297>,
			<13517 13471 13399 13331 13301 13296>,
			<13526 13464 13389 13333 13301 13295>,
			<13533 13454 13382 13334 13300 13293>,
			<13539 13435 13377 13328 13298 13288>,
			<13543 13421 13372 13320 13294 13284>,
			<13536 13421 13367 13316 13291 13282>,
			<13517 13422 13362 13312 13288 13280>,
			<13511 13420 13359 13311 13287 13280>,
			<13515 13396 13356 13311 13287 13280>,
			<13523 13376 13355 13311 13287 13280>,
			<13533 13375 13356 13311 13287 13280>,
			<13549 13375 13357 13312 13287 13279>,
			<13568 13377 13356 13312 13287 13278>,
			<13594 13388 13350 13314 13288 13279>,
			<13621 13403 13347 13315 13289 13280>,
			<13644 13413 13350 13316 13290 13281>,
			<13666 13424 13354 13316 13290 13282>,
			<13692 13437 13357 13317 13290 13282>,
			<13722 13453 13359 13317 13289 13280>,
			<13758 13471 13361 13316 13288 13279>,
			<13801 13490 13365 13314 13286 13279>,
			<13851 13512 13368 13311 13285 13279>,
			<13899 13541 13369 13311 13285 13280>,
			<13948 13580 13370 13312 13285 13281>,
			<14005 13635 13368 13312 13286 13282>,
			<14062 13703 13365 13312 13286 13281>,
			<14090 13749 13362 13309 13284 13278>,
			<14011 13749 13362 13311 13290 13283>,
			<14094 13843 13371 13315 13291 13287>,
			<14174 13930 13381 13317 13293 13288>,
			<14258 14024 13392 13324 13299 13295>,
			<14366 14114 13407 13327 13299 13291>,
			<14517 14205 13405 13327 13295 13287>,
			<14742 14338 13409 13328 13299 13290>,
			<15124 14553 13480 13337 13305 13294>,
			<16211 14822 13606 13348 13309 13298>,
			<16211 14822 13606 13348 13309 13298>,
			<16211 14822 13606 13348 13309 13298>;
	};

	qcom,pc-temp-y4-lut {
		qcom,lut-col-legend = <(-10) 0 10 25 40 50>;
		qcom,lut-row-legend = <10000 9800 9600 9400 9200 9000>,
			<8800 8600 8400 8200 8000 7800>,
			<7600 7400 7200 7000 6800 6600>,
			<6400 6200 6000 5800 5600 5400>,
			<5200 5000 4800 4600 4400 4200>,
			<4000 3800 3600 3400 3200 3000>,
			<2800 2600 2400 2200 2000 1800>,
			<1600 1400 1200 1000 900 800>,
			<700 600 500 400 300 200>,
			<100 0>;
		qcom,lut-data = <17122 16977 16665 16501 16481 16477>,
			<17325 16989 16667 16506 16476 16471>,
			<17448 17000 16669 16513 16472 16467>,
			<17510 17011 16672 16519 16470 16465>,
			<17532 17022 16674 16523 16469 16463>,
			<17535 17032 16677 16525 16469 16463>,
			<17458 17043 16679 16524 16471 16466>,
			<17348 17052 16683 16524 16473 16469>,
			<17316 17040 16690 16528 16478 16469>,
			<17304 16988 16703 16538 16485 16467>,
			<17303 16964 16714 16549 16493 16466>,
			<17467 17073 16721 16558 16502 16471>,
			<17670 17204 16731 16570 16511 16480>,
			<17593 17212 16765 16587 16517 16489>,
			<17253 17187 16830 16610 16523 16500>,
			<17081 17144 16852 16631 16531 16510>,
			<17076 16998 16820 16652 16547 16517>,
			<17085 16860 16772 16668 16569 16524>,
			<17089 16849 16723 16676 16597 16545>,
			<17091 16849 16668 16682 16629 16574>,
			<17076 16846 16636 16679 16632 16580>,
			<17021 16828 16617 16607 16581 16551>,
			<16966 16800 16606 16533 16527 16517>,
			<16946 16768 16599 16514 16499 16492>,
			<16933 16732 16594 16504 16479 16471>,
			<16928 16705 16593 16502 16475 16467>,
			<16929 16683 16593 16504 16478 16469>,
			<16931 16671 16593 16507 16482 16473>,
			<16931 16672 16588 16512 16490 16481>,
			<16931 16675 16580 16519 16502 16493>,
			<16929 16683 16574 16527 16514 16504>,
			<16918 16717 16570 16535 16527 16516>,
			<16909 16748 16568 16542 16536 16526>,
			<16910 16763 16571 16546 16544 16538>,
			<16912 16774 16577 16549 16548 16547>,
			<16914 16782 16585 16548 16541 16537>,
			<16915 16787 16597 16539 16511 16497>,
			<16917 16792 16608 16529 16491 16474>,
			<16924 16800 16617 16522 16483 16469>,
			<16935 16807 16624 16517 16479 16466>,
			<16948 16806 16625 16516 16483 16469>,
			<16965 16799 16626 16520 16492 16475>,
			<16986 16791 16623 16526 16493 16475>,
			<17008 16784 16616 16532 16489 16472>,
			<17000 16777 16590 16510 16467 16455>,
			<16931 16775 16598 16509 16472 16465>,
			<16947 16790 16614 16521 16485 16472>,
			<16966 16817 16641 16542 16500 16485>,
			<16982 16859 16683 16565 16515 16497>,
			<16985 16907 16736 16576 16512 16491>,
			<16970 16918 16728 16552 16484 16466>,
			<16960 16876 16741 16554 16479 16466>,
			<16988 16863 16777 16572 16492 16476>,
			<17361 16880 16836 16618 16535 16524>,
			<17361 16880 16836 16618 16535 16524>,
			<17361 16880 16836 16618 16535 16524>;
	};

	qcom,pc-temp-y5-lut {
		qcom,lut-col-legend = <(-10) 0 10 25 40 50>;
		qcom,lut-row-legend = <10000 9800 9600 9400 9200 9000>,
			<8800 8600 8400 8200 8000 7800>,
			<7600 7400 7200 7000 6800 6600>,
			<6400 6200 6000 5800 5600 5400>,
			<5200 5000 4800 4600 4400 4200>,
			<4000 3800 3600 3400 3200 3000>,
			<2800 2600 2400 2200 2000 1800>,
			<1600 1400 1200 1000 900 800>,
			<700 600 500 400 300 200>,
			<100 0>;
		qcom,lut-data = <11990 11248 13399 17403 15338 13921>,
			<11576 11487 13807 16381 15909 14454>,
			<11394 11851 14075 15404 16280 14819>,
			<11396 12242 14225 14580 16494 15044>,
			<11539 12564 14283 14015 16591 15156>,
			<11781 12718 14273 13820 16612 15182>,
			<12750 12749 14112 14067 16473 14968>,
			<13895 12774 13912 14373 16190 14695>,
			<13888 13186 13828 14241 15813 15038>,
			<13221 14601 13708 13816 15240 16353>,
			<12874 15283 13665 13503 14692 16941>,
			<12937 14128 13846 13340 14113 16433>,
			<13095 12745 14143 13214 13707 15644>,
			<14286 13699 14395 13084 13789 14916>,
			<17717 17235 14685 12881 14095 14159>,
			<19163 18699 15285 12820 14183 13934>,
			<16208 16637 17610 13280 13707 14106>,
			<12827 14447 19590 14156 13239 14267>,
			<12437 14525 19130 15901 13361 14131>,
			<12535 15164 17868 18695 13860 13797>,
			<12632 15472 17269 19699 14749 13861>,
			<12737 15494 17098 19671 17247 15521>,
			<12821 15533 16920 19547 19033 17040>,
			<12563 16613 16457 18791 18460 17387>,
			<11865 18939 15888 17151 17287 17617>,
			<11536 19343 15742 16421 16757 17574>,
			<11456 15869 15771 16487 16523 17032>,
			<11424 12853 15854 16662 16371 16397>,
			<11424 12680 16701 16676 16015 15582>,
			<11425 12629 17965 16703 15544 14747>,
			<11450 12501 17849 16869 15526 14630>,
			<11651 12188 16306 17586 15895 14756>,
			<11816 11997 15455 18417 16310 14953>,
			<11814 12019 15883 19159 16778 15399>,
			<11801 12081 16510 19808 17244 16013>,
			<11791 12205 16836 20002 17524 16589>,
			<11784 12513 17070 19998 17840 17188>,
			<11771 12738 17338 19838 17895 17446>,
			<11720 12776 17800 18597 17185 17356>,
			<11649 12766 18176 16834 16212 17144>,
			<11642 12749 18084 16341 15553 16708>,
			<11687 12719 17666 16219 15020 16077>,
			<11789 12624 16981 15841 14784 16101>,
			<11909 12423 15796 15247 15094 15943>,
			<12153 12325 15329 15007 15532 16283>,
			<12258 12154 14650 15395 16408 15942>,
			<12441 12363 15014 15557 15254 15931>,
			<12682 12585 15234 14905 14475 15286>,
			<12903 12856 15420 15043 14932 16836>,
			<13015 13012 16029 15402 15448 16133>,
			<12855 12934 15129 16444 16186 16723>,
			<12688 12583 12941 17186 18345 18764>,
			<12510 12430 12914 18552 21337 20459>,
			<11551 12367 12970 19759 21507 22241>,
			<11551 12367 12970 19759 21507 22241>,
			<11551 12367 12970 19759 21507 22241>;
	};

	qcom,pc-temp-y6-lut {
		qcom,lut-col-legend = <(-10) 0 10 25 40 50>;
		qcom,lut-row-legend = <10000 9800 9600 9400 9200 9000>,
			<8800 8600 8400 8200 8000 7800>,
			<7600 7400 7200 7000 6800 6600>,
			<6400 6200 6000 5800 5600 5400>,
			<5200 5000 4800 4600 4400 4200>,
			<4000 3800 3600 3400 3200 3000>,
			<2800 2600 2400 2200 2000 1800>,
			<1600 1400 1200 1000 900 800>,
			<700 600 500 400 300 200>,
			<100 0>;
		qcom,lut-data = <7001 5927 5381 5112 5046 5030>,
			<6940 5922 5377 5111 5046 5030>,
			<6882 5916 5374 5111 5046 5030>,
			<6827 5909 5370 5111 5047 5031>,
			<6776 5901 5366 5111 5048 5031>,
			<6728 5893 5362 5111 5049 5032>,
			<6685 5883 5357 5113 5050 5033>,
			<6644 5873 5353 5114 5052 5035>,
			<6599 5867 5352 5116 5054 5037>,
			<6550 5862 5352 5119 5056 5039>,
			<6521 5860 5353 5122 5059 5041>,
			<6512 5859 5354 5125 5061 5044>,
			<6505 5858 5356 5129 5064 5046>,
			<6476 5857 5363 5134 5067 5048>,
			<6412 5853 5377 5142 5072 5051>,
			<6359 5844 5382 5149 5076 5054>,
			<6323 5795 5372 5155 5080 5058>,
			<6299 5746 5358 5160 5084 5062>,
			<6295 5742 5339 5164 5091 5067>,
			<6293 5742 5316 5167 5100 5074>,
			<6291 5741 5302 5167 5101 5075>,
			<6284 5733 5294 5142 5084 5063>,
			<6277 5727 5289 5116 5065 5049>,
			<6271 5728 5286 5108 5055 5041>,
			<6267 5733 5284 5104 5047 5033>,
			<6267 5734 5284 5103 5046 5032>,
			<6282 5730 5286 5104 5047 5033>,
			<6304 5727 5288 5106 5049 5034>,
			<6323 5736 5292 5109 5051 5036>,
			<6343 5762 5296 5112 5054 5039>,
			<6364 5786 5298 5116 5058 5043>,
			<6385 5810 5299 5121 5063 5046>,
			<6408 5836 5302 5125 5067 5050>,
			<6432 5864 5310 5129 5070 5055>,
			<6458 5893 5322 5132 5072 5058>,
			<6484 5925 5334 5132 5070 5055>,
			<6511 5961 5348 5131 5061 5043>,
			<6542 5999 5362 5129 5055 5036>,
			<6581 6041 5377 5127 5052 5034>,
			<6626 6087 5393 5124 5050 5034>,
			<6671 6137 5410 5125 5051 5035>,
			<6717 6193 5427 5129 5054 5038>,
			<6771 6257 5445 5133 5056 5039>,
			<6827 6328 5464 5136 5056 5038>,
			<6855 6378 5460 5130 5048 5031>,
			<6798 6390 5479 5132 5054 5037>,
			<6872 6468 5512 5140 5059 5042>,
			<6940 6552 5551 5149 5064 5048>,
			<7013 6645 5594 5162 5073 5056>,
			<7108 6736 5648 5169 5072 5052>,
			<7234 6819 5669 5163 5062 5042>,
			<7422 6923 5722 5169 5064 5044>,
			<7764 7097 5854 5187 5073 5051>,
			<8885 7332 6047 5215 5090 5069>,
			<8885 7332 6047 5215 5090 5069>,
			<8885 7332 6047 5215 5090 5069>;
	};
};
